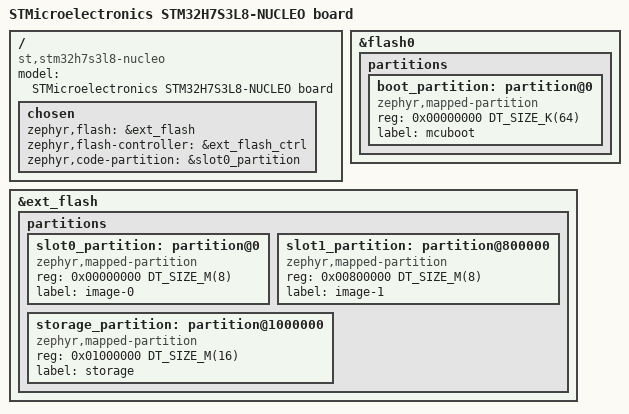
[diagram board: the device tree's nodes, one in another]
/*
 * Copyright (c) 2024 STMicroelectronics
 * Copyright (c) 2025 JB-Lighting Lichtanlagentechnik
 *
 * SPDX-License-Identifier: Apache-2.0
 */

/dts-v1/;
#include "nucleo_h7s3l8-common.dtsi"

/ {
	compatible = "st,stm32h7s3l8-nucleo";
	model = "STMicroelectronics STM32H7S3L8-NUCLEO board";

	chosen {
		zephyr,flash = &ext_flash;
		zephyr,flash-controller = &ext_flash_ctrl;
		zephyr,code-partition = &slot0_partition;
	};
};

&flash0 {
	partitions {
		ranges;
		#address-cells = <1>;
		#size-cells = <1>;

		boot_partition: partition@0 {
			compatible = "zephyr,mapped-partition";
			reg = <0x00000000 DT_SIZE_K(64)>;
			label = "mcuboot";
		};
	};
};

&ext_flash {
	status = "okay";

	partitions {
		ranges;
		#address-cells = <1>;
		#size-cells = <1>;

		slot0_partition: partition@0 {
			compatible = "zephyr,mapped-partition";
			reg = <0x00000000 DT_SIZE_M(8)>;
			label = "image-0";
		};

		slot1_partition: partition@800000 {
			compatible = "zephyr,mapped-partition";
			reg = <0x00800000 DT_SIZE_M(8)>;
			label = "image-1";
		};

		storage_partition: partition@1000000 {
			compatible = "zephyr,mapped-partition";
			reg = <0x01000000 DT_SIZE_M(16)>;
			label = "storage";
		};
	};
};
